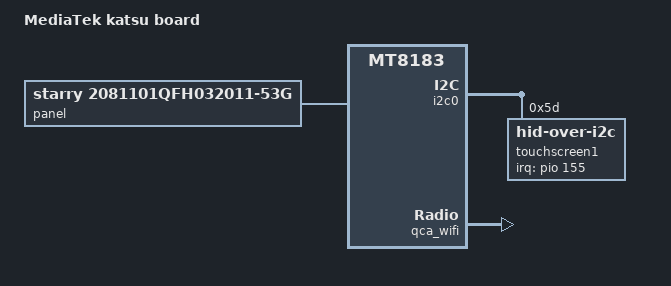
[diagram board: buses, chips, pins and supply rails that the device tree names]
// SPDX-License-Identifier: (GPL-2.0 OR MIT)
/*
 * Copyright 2021 Google LLC
 */

/dts-v1/;
#include "mt8183-kukui-kakadu.dtsi"
#include "mt8183-kukui-audio-da7219-rt1015p.dtsi"

/ {
	model = "MediaTek katsu board";
	compatible = "google,katsu", "mediatek,mt8183";
};

&i2c0 {
	status = "okay";

	touchscreen1: touchscreen@5D {
		compatible = "hid-over-i2c";
		reg = <0x5D>;
		pinctrl-names = "default";
		pinctrl-0 = <&open_touch>;

		interrupt-parent = <&pio>;
		interrupts = <155 IRQ_TYPE_EDGE_FALLING>;

		post-power-on-delay-ms = <10>;
		hid-descr-addr = <0x0001>;
	};
};

&panel {
	compatible = "starry,2081101qfh032011-53g";
};

&qca_wifi {
	qcom,ath10k-calibration-variant = "GO_KATSU";
};
